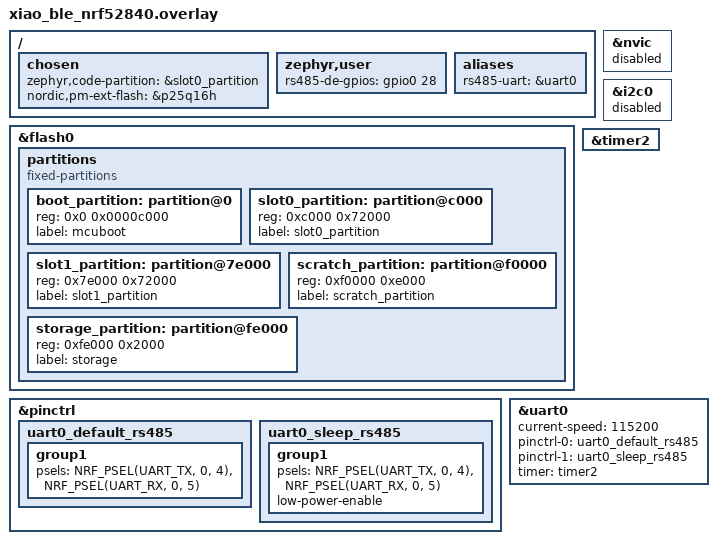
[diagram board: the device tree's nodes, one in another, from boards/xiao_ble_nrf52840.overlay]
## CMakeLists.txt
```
cmake_minimum_required(VERSION 3.20.0)

# BLE pairing passkey is injected at build time from the environment so it is
# never committed to source. The build fails (here, before the rest of the
# configure) if the variable is unset. The value must be a 6-digit number (the
# BLE passkey format; tools/ble-client reads the same variable). It is later
# passed to the app as a string literal and parsed in src/ble_transport.c so a
# value with leading zeros is not read as octal.
if(NOT DEFINED ENV{FLEXIT_CS60_CONTROL_BLE_KEY})
    message(FATAL_ERROR
        "FLEXIT_CS60_CONTROL_BLE_KEY is not set. Export the 6-digit BLE pairing "
        "passkey before building, e.g.\n"
        "    export FLEXIT_CS60_CONTROL_BLE_KEY=444999")
endif()
set(ble_passkey "$ENV{FLEXIT_CS60_CONTROL_BLE_KEY}")
if(NOT ble_passkey MATCHES "^[0-9][0-9][0-9][0-9][0-9][0-9]$")
    message(FATAL_ERROR
        "FLEXIT_CS60_CONTROL_BLE_KEY must be a 6-digit number (got '${ble_passkey}').")
endif()

# Zigbee was removed from the main NCS in v3.0 and now ships as the out-of-tree
# ncs-zigbee add-on. Register it as an extra Zephyr module so the app image can
# pull in the ZBOSS stack. Override on the command line with
# -DZEPHYR_EXTRA_MODULES=<path> if the add-on lives elsewhere.
if(NOT DEFINED ZEPHYR_EXTRA_MODULES)
    set(ZEPHYR_EXTRA_MODULES "$ENV{HOME}/ncs/v3.4.0/ncs-zigbee")
endif()

find_package(Zephyr REQUIRED HINTS $ENV{ZEPHYR_BASE})

project(flexit-cs60-control)

# Bake the validated passkey (checked at the top of this file) into the app as a
# string literal; src/ble_transport.c parses it. zephyr_compile_definitions is
# only available after find_package(Zephyr), hence the split from the check.
zephyr_compile_definitions(FLEXIT_BLE_PASSKEY="${ble_passkey}")

# ZBOSS's built-in "include all ZCL clusters" set (ncs-zigbee zb_vendor.h) omits
# Analog Input, so its server (zcl_analog_input.c) is not compiled and its
# init_server symbol is missing at link. Define the support flag image-wide so
# the cluster source is built and the API header is pulled in. Used by the
# percentage Analog Input endpoints (EP5/EP6) in src/zigbee_ep.c.
zephyr_compile_definitions(ZB_ZCL_SUPPORT_CLUSTER_ANALOG_INPUT)

# Likewise Analog Value (0x000E) is omitted from the built-in set; it backs the
# writable temperature-setpoint endpoint (EP7) in src/zigbee_ep.c.
zephyr_compile_definitions(ZB_ZCL_SUPPORT_CLUSTER_ANALOG_VALUE)

target_sources(app PRIVATE
    src/main.c
    src/ble_transport.c
    src/flexit_bridge.c
    src/flexit_slave.c
    src/panel_mirror.c
    src/rs485_uart.c
    src/zigbee_ep.c
)
```

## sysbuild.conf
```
# Enable MCUboot bootloader compilation via Sysbuild
SB_CONFIG_BOOTLOADER_MCUBOOT=y

# The Zigbee add-on requires Partition Manager (it selects PM_SINGLE_IMAGE and
# addresses the ZBOSS NVRAM via PM_* partitions). Enable it and provide the
# layout in pm_static_xiao_ble_nrf52840.yml. MCUboot defaults to
# swap-using-move, so no scratch partition is needed.
SB_CONFIG_PARTITION_MANAGER=y

# Place the MCUboot secondary (DFU staging) slot in the XIAO BLE's onboard 2 MB
# QSPI flash instead of internal flash. This frees ~half of the 1 MB internal
# flash so the BLE + Zigbee image fits comfortably in a single large primary
# slot. Requires nordic,pm-ext-flash chosen in the app + mcuboot DTS overlays
# and the QSPI NOR driver in both images.
SB_CONFIG_PM_EXTERNAL_FLASH_MCUBOOT_SECONDARY=y
```

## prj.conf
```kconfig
CONFIG_GPIO=y
CONFIG_BOOTLOADER_MCUBOOT=y

# Logging via the existing CDC-ACM console (printk goes here too).
CONFIG_LOG=y

# --- MCUmgr / SMP server over the CDC-ACM UART ---
# The board already chooses zephyr,uart-mcumgr = &board_cdc_acm_uart,
# so the UART transport lands on USB CDC-ACM automatically.
CONFIG_MCUMGR=y
# Since NCS v3.4.0 MCUMGR_TRANSPORT_UART *depends on* UART_MCUMGR (it used to
# select it). Without this line the UART transport is silently dropped and USB
# DFU recovery is lost — keep it.
CONFIG_UART_MCUMGR=y
CONFIG_MCUMGR_TRANSPORT_UART=y

# Command groups exposed over SMP.
# Image upload/list/test/confirm; OS reset is part of the OS group.
CONFIG_MCUMGR_GRP_IMG=y
CONFIG_MCUMGR_GRP_OS=y

# Backing store for image uploads: writes the blob into MCUboot's secondary slot.
CONFIG_IMG_MANAGER=y
CONFIG_STREAM_FLASH=y
CONFIG_FLASH=y
CONFIG_FLASH_MAP=y

# Dependencies pulled in by MCUmgr.
CONFIG_ZCBOR=y
CONFIG_BASE64=y
CONFIG_CRC=y

# A bit more stack/heap for the SMP processing thread and BLE host work.
CONFIG_MAIN_STACK_SIZE=4096
CONFIG_SYSTEM_WORKQUEUE_STACK_SIZE=4096

# RS-485 receive on UART0 (D4=RX, D5=TX, D2=DE/RE) via the
# XIAO-RS485-Expansion-Board. The async UART API drives the UARTE peripheral
# in continuous DMA mode (double-buffered, 256 B per buffer = ~22 ms of
# headroom at 115200 baud) so long bursts can't be lost while BLE host work
# briefly delays the application.
CONFIG_SERIAL=y
CONFIG_UART_ASYNC_API=y
# MCUMGR_TRANSPORT_UART forces UART_INTERRUPT_DRIVEN=y globally for the
# CDC-ACM console, which would also pick uart0 into IRQ mode and lock
# UART_0_ASYNC out. Pin uart0 to async-only here.
CONFIG_UART_0_INTERRUPT_DRIVEN=n
CONFIG_RING_BUFFER=y

# --- Bluetooth Low Energy ---
# Peripheral that exposes:
#   - SMP service (DFU over BLE, gated by passkey-authenticated pairing)
#   - Nordic UART Service (console output mirror)
CONFIG_BT=y
CONFIG_BT_PERIPHERAL=y
CONFIG_BT_DEVICE_NAME="flexit-cs60-control"
CONFIG_BT_MAX_CONN=1
CONFIG_BT_RX_STACK_SIZE=2048

# Security Manager + app-provided passkey (set at build time from
# $FLEXIT_CS60_CONTROL_BLE_KEY, see CMakeLists.txt). Bonding is enabled and persisted in NVS
# (storage_partition in the board overlay) so macOS can reconnect using the
# stored LTK without a fresh passkey prompt. The storage partition lives at
# the end of flash, outside MCUboot's slots/scratch, so the bond survives
# firmware DFU swaps as well.
CONFIG_BT_SMP=y
CONFIG_BT_APP_PASSKEY=y
CONFIG_BT_BONDABLE=y

# LE Secure Connections generates a P-256 key pair via the PSA crypto stack
# (nRF Security). Two resources must be sized for this, or BLE pairing — and
# therefore BLE DFU — fails:
#   1. mbedTLS heap. The Kconfig default (512 B) is far too small:
#      psa_generate_key() fails with PSA_ERROR_INSUFFICIENT_MEMORY (-141), the
#      local public key is never produced, and SC pairing stalls after the
#      peer's public key arrives, timing out after 30 s.
#   2. The BLE "long workqueue" stack. ecc.c runs the (stack-heavy) P-256
#      keygen on bt_long_wq; the 1800 B default overflows mid-keygen once the
#      heap is large enough for the computation to actually run, tripping the
#      MPU stack guard and faulting at boot.
# Sized here for ECC keygen alongside the concurrent Zigbee/ZBOSS crypto. 8192
# was enough on a freshly-booted device but still too tight in the field: it
# shares the heap with active ZBOSS crypto, so once Zigbee has consumed heap a
# *fresh* SC pairing intermittently stalls at -141 (a just-booted device pairs
# fine, and bond reuse needs no keygen, both of which masked it). 16384 gives
# keygen headroom over concurrent ZBOSS.
CONFIG_MBEDTLS_HEAP_SIZE=16384
CONFIG_BT_LONG_WQ_STACK_SIZE=4096

# Always-on device: reboot on a fatal error instead of halting. Also makes an
# unconfirmed DFU test image that faults revert cleanly on the auto-reset
# (MCUboot swaps the previous good image back) rather than wedging the board.
CONFIG_RESET_ON_FATAL_ERROR=y
CONFIG_BT_SETTINGS=y
CONFIG_BT_KEYS_OVERWRITE_OLDEST=y
CONFIG_SETTINGS=y
CONFIG_SETTINGS_NVS=y
CONFIG_NVS=y
CONFIG_FLASH_PAGE_LAYOUT=y

# Larger MTU/ACL buffers for faster DFU throughput.
CONFIG_BT_L2CAP_TX_MTU=498
CONFIG_BT_BUF_ACL_RX_SIZE=502
CONFIG_BT_BUF_ACL_TX_SIZE=502
CONFIG_BT_ATT_PREPARE_COUNT=2

# --- BLE DFU throughput ---
# The big MTU/buffers above are wasted without these. By default the link-layer
# payload (DLE) is capped at 27 B, the connection stays at the central's slow
# default interval, and the radio uses the 1M PHY — so a ~0.5 MB image takes
# ~13 min over BLE. Together these take it to well under a minute:
#   - DLE up to 251 B link-layer payloads (BT_AUTO_DATA_LEN_UPDATE already on).
#   - Auto-switch to the 2M PHY (controller already advertises 2M support).
#   - Let MCUmgr request a fast connection interval while a DFU is in progress.
#   - Advertise SMP buffer params so a client can size its chunks.
#   - Erase the secondary slot progressively instead of all up front.
CONFIG_BT_CTLR_DATA_LENGTH_MAX=251
CONFIG_BT_AUTO_PHY_UPDATE=y
CONFIG_MCUMGR_TRANSPORT_BT_CONN_PARAM_CONTROL=y
CONFIG_MCUMGR_GRP_OS_MCUMGR_PARAMS=y
CONFIG_IMG_ERASE_PROGRESSIVELY=y

# Nordic UART Service (NCS). Gate it to authenticated (passkey-paired)
# connections, same as the SMP transport below. Without this the NUS RX/TX
# characteristics default to plain READ|WRITE permissions, so commands are
# serviced over an unencrypted link before the firmware-initiated security
# upgrade resolves — leaking panel state and accepting mode/setpoint/zbreset
# from unpaired centrals, and making `state` pairing race (unlike `list`,
# whose auth-gated SMP access drives pairing deterministically).
CONFIG_BT_NUS=y
CONFIG_BT_NUS_AUTHEN=y

# SMP/MCUmgr transport over BLE — gated to authenticated (passkey-paired)
# connections only; pair-less centrals get permission errors.
CONFIG_MCUMGR_TRANSPORT_BT=y
CONFIG_MCUMGR_TRANSPORT_BT_REASSEMBLY=y
CONFIG_MCUMGR_TRANSPORT_BT_PERM_RW_AUTHEN=y

# MCUmgr image-upload notification hooks: let the app suspend the Zigbee stack
# while a DFU upload is in flight so the shared 2.4 GHz radio is handed to BLE.
# As a router the 802.15.4 side keeps the radio busy (continuous RX, relaying,
# channel scans), which starves the BLE link and times out a sustained DFU
# upload; zigbee_ep.c hooks DFU_STARTED/STOPPED to suspend/resume ZBOSS. See
# CONFIG_ZIGBEE_DEBUG_FUNCTIONS below.
CONFIG_MCUMGR_MGMT_NOTIFICATION_HOOKS=y
CONFIG_MCUMGR_GRP_IMG_STATUS_HOOKS=y

# Route printk through the log subsystem so the NUS log backend can mirror
# it over BLE. The default UART log backend keeps the USB CDC console alive.
CONFIG_LOG_PRINTK=y
CONFIG_LOG_MODE_DEFERRED=y
CONFIG_LOG_BACKEND_UART=y

# --- Zigbee (802.15.4) router, concurrent with BLE via MPSL ---
# The ncs-zigbee add-on (registered as an extra Zephyr module in CMakeLists)
# provides the ZBOSS stack. This runs a router alongside the BLE peripheral;
# MPSL/the SoftDevice Controller arbitrate the shared radio. Partition layout is
# in pm_static_xiao_ble_nrf52840.yml.
#
# Router (not end device): the XIAO is permanently USB-powered, so there is no
# battery reason to be an end device — and the end-device role caused HA fan/
# setpoint writes to fail. An rx-on-when-idle end device has a single parent and
# relies on it both to deliver downstream frames and to answer route requests on
# its behalf. When the parent ages the child out (or the parent link goes stale)
# the coordinator gets NO_ROUTE / ROUTE_DISCOVERY_UNDERWAY and downstream writes
# die, while the device still blindly pushes reports upstream — so sensors keep
# updating but control silently breaks. A router maintains its own routes (link
# status / route records), is always directly addressable, and is never aged out
# as someone's child, which removes that whole failure class. (Diagnosed from a
# ZHA debug log: cluster 0x0202 FanMode writes to the XIAO returned NO_ROUTE.)
# NOTE: switching role changes the device type in the PAN, so the device must
# leave and re-pair (zbreset + ZHA permit-join) after flashing this build.
CONFIG_ZIGBEE_ADD_ON=y
CONFIG_ZIGBEE_APP_UTILS=y
CONFIG_ZIGBEE_ROLE_ROUTER=y

# Compile in zigbee_debug_suspend/resume_zboss_thread(). zigbee_ep.c calls these
# from the MCUmgr DFU hooks (above) to hand the radio to BLE during a firmware
# upload. The device resets after a successful DFU, so suspending ZBOSS across
# the upload is harmless; an aborted upload resumes it. (The Kconfig help warns
# these can cause instability if misused — here they are only ever used around a
# DFU that ends in a reboot.)
CONFIG_ZIGBEE_DEBUG_FUNCTIONS=y

# Scan all 802.15.4 channels (11-26) to find the Home Assistant coordinator's
# network, rather than the default single-channel (16) mode. Nordic recommends
# CHANNEL_SELECTION_MODE_MULTI when joining a third-party coordinator (ZHA/Z2M),
# since we don't control which channel HA forms its network on.
CONFIG_ZIGBEE_CHANNEL_SELECTION_MODE_MULTI=y

# How long the zigbee is open for pairing after reset/start, when device is not 
# previously paired, or zbreset has been used.
CONFIG_ZIGBEE_DEV_REJOIN_TIMEOUT_MS=60000

# ZBOSS needs a bit more heap than the BLE-only build.
CONFIG_HEAP_MEM_POOL_SIZE=2048

# QSPI NOR driver — the MCUboot DFU secondary slot lives in the XIAO BLE's
# onboard 2 MB QSPI flash (p25q16h), so the app must be able to write the
# uploaded image there via the flash map. This moves the dual-slot pressure off
# the 1 MB internal flash; see smarthouse-integration.md "flash budget".
CONFIG_NORDIC_QSPI_NOR=y
CONFIG_NORDIC_QSPI_NOR_FLASH_LAYOUT_PAGE_SIZE=4096
```

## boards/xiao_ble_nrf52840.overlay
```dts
#include <zephyr/dt-bindings/gpio/gpio.h>

/ {
	chosen {
		zephyr,code-partition = &slot0_partition;
		/* MCUboot DFU secondary slot lives in the onboard 2 MB QSPI flash. */
		nordic,pm-ext-flash = &p25q16h;
	};

	zephyr,user {
		/* XIAO-RS485-Expansion-Board: D2 = SP3485 DE/RE.
		 * HIGH = drive bus (transmit), LOW = high-Z receive.
		 */
		rs485-de-gpios = <&gpio0 28 GPIO_ACTIVE_HIGH>;
	};

	aliases {
		rs485-uart = &uart0;
	};
};

/delete-node/ &code_partition;
/delete-node/ &reserved_partition_0;
/delete-node/ &boot_partition;
/delete-node/ &storage_partition;

&flash0 {
	partitions {
		compatible = "fixed-partitions";
		#address-cells = <1>;
		#size-cells = <1>;

		boot_partition: partition@0 {
			reg = <0x0 0x0000c000>;
			label = "mcuboot";
		};

		slot0_partition: partition@c000 {
			reg = <0xc000 0x72000>;
			label = "slot0_partition";
		};

		slot1_partition: partition@7e000 {
			reg = <0x7e000 0x72000>;
			label = "slot1_partition";
		};

		scratch_partition: partition@f0000 {
			reg = <0xf0000 0xe000>;
			label = "scratch_partition";
		};

		storage_partition: partition@fe000 {
			reg = <0xfe000 0x2000>;
			label = "storage";
		};
	};
};

&nvic {
	status = "disabled";
};

/* The board enables I2C0 on P0.04/P0.05 by default; the RS485 expansion
 * uses those same pins for UART RX/TX, so I2C0 has to release them.
 */
&i2c0 {
	status = "disabled";
};

&pinctrl {
	uart0_default_rs485: uart0_default_rs485 {
		group1 {
			psels = <NRF_PSEL(UART_TX, 0, 4)>,
				<NRF_PSEL(UART_RX, 0, 5)>;
		};
	};

	uart0_sleep_rs485: uart0_sleep_rs485 {
		group1 {
			psels = <NRF_PSEL(UART_TX, 0, 4)>,
				<NRF_PSEL(UART_RX, 0, 5)>;
			low-power-enable;
		};
	};
};

/* TIMER2 is dedicated to UARTE0 as the RX byte counter for the async
 * UART API. Without this, the driver can't reliably count incoming
 * bytes when the bus runs without hardware flow control, and long
 * frames get truncated at buffer-switch boundaries.
 */
&timer2 {
	status = "okay";
};

&uart0 {
	status = "okay";
	current-speed = <115200>;
	pinctrl-0 = <&uart0_default_rs485>;
	pinctrl-1 = <&uart0_sleep_rs485>;
	pinctrl-names = "default", "sleep";
	timer = <&timer2>;
};
```

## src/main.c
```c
#include <zephyr/kernel.h>
#include <zephyr/drivers/gpio.h>
#include <zephyr/drivers/watchdog.h>
#include <zephyr/sys/printk.h>
#include <zephyr/sys/reboot.h>
#include <zephyr/task_wdt/task_wdt.h>

#include "ble_transport.h"
#include "flexit_bridge.h"
#include "flexit_slave.h"
#include "panel_mirror.h"
#include "rs485_uart.h"
#include "zigbee_ep.h"

static const struct gpio_dt_spec red_led =
    GPIO_DT_SPEC_GET(DT_ALIAS(led0), gpios);
static const struct gpio_dt_spec green_led =
    GPIO_DT_SPEC_GET(DT_ALIAS(led1), gpios);
static const struct gpio_dt_spec blue_led =
    GPIO_DT_SPEC_GET(DT_ALIAS(led2), gpios);

/* Status-LED timing. The loop ticks at the fast-blink period; the slower
 * cadences are multiples of it. */
#define LED_TICK_MS          100   /* loop period == fast (joining) blink step */
#define LED_SLOW_BLINK_TICKS 10    /* idle blink: toggle every 1 s            */
#define RED_BLINK_TICKS      5     /* RS485-fault blink: toggle every 500 ms   */
#define ADV_ENSURE_TICKS     10    /* re-check advertising about once a second */

/* The CS60 broadcasts its FC10 status frame continuously (well under a second
 * apart). Treat the RS485 link as down if no valid frame has arrived for this
 * long — generous enough to ride out occasional CRC drops, short enough that a
 * pulled cable or wrong wiring shows on the LED within a few seconds. */
#define RS485_CS60_STALE_MS  5000

/* ---------------------------------------------------------------------------
 * Watchdog
 *
 * The diagnosed field failure is a wedged *system workqueue* (the RS485 drain
 * and Zigbee bridge both run there) while the BLE/SMP threads keep answering —
 * so a watchdog fed only from main() would never fire: main() keeps spinning.
 * We run two task-wdt channels backed by the nRF hardware WDT:
 *   - channel 0 (main): fed every tick from the loop below — catches a hung
 *                       main thread.
 *   - channel 1 (wq):   fed by a heartbeat work item on the system workqueue —
 *                       catches the workqueue wedge, which is the actual fault.
 * task_wdt's expiry runs in the kernel-timer ISR (independent of the
 * workqueue), so a starved channel reboots the SoC even when the workqueue is
 * stuck; MCUboot then re-runs the confirmed image. This automates the manual
 * `ble-client reboot` recovery.
 *
 * Periods are generous: a feed merely has to land within them. The wq heartbeat
 * reschedules far more often than its channel period so ordinary TX stalls in
 * the drain path don't false-trip; only a true wedge (stuck forever inside one
 * work item) lets the channel lapse.
 * ---------------------------------------------------------------------------
 */
#define WDT_MAIN_FEED_PERIOD_MS  5000   /* main loop ticks every LED_TICK_MS */
#define WDT_WQ_HEARTBEAT_MS      1000   /* heartbeat reschedule cadence       */
#define WDT_WQ_FEED_PERIOD_MS    8000   /* workqueue stall tolerated before reset */

static const struct device *const wdt_dev = DEVICE_DT_GET(DT_ALIAS(watchdog0));
static int wdt_main_chan = -1;
static int wdt_wq_chan   = -1;

/* Breadcrumb left for the next boot to report which channel tripped. __noinit
 * RAM survives the cold reset; validated by a magic to ignore power-on garbage. */
static __noinit volatile uint32_t wdt_trip_marker;
#define WDT_TRIP_MAGIC 0x5744u  /* 'WD' */

static const char *wdt_chan_name(uint32_t ch)
{
    switch (ch) {
    case 0:  return "main loop";
    case 1:  return "system-workqueue heartbeat";
    default: return "?";
    }
}

/* Runs in the task_wdt kernel-timer ISR when a channel starves. Deferred
 * logging can't flush here, so leave a RAM breadcrumb, then cold-reset. */
static void wdt_timeout_cb(int channel_id, void *user_data)
{
    ARG_UNUSED(user_data);
    wdt_trip_marker = WDT_TRIP_MAGIC | ((uint32_t)(channel_id & 0xFF) << 16);
    sys_reboot(SYS_REBOOT_COLD);
}

static void wdt_wq_heartbeat_fn(struct k_work *work);
static K_WORK_DELAYABLE_DEFINE(wdt_wq_heartbeat, wdt_wq_heartbeat_fn);

static void wdt_wq_heartbeat_fn(struct k_work *work)
{
    ARG_UNUSED(work);
    if (wdt_wq_chan >= 0) {
        (void)task_wdt_feed(wdt_wq_chan);
    }
    k_work_reschedule(&wdt_wq_heartbeat, K_MSEC(WDT_WQ_HEARTBEAT_MS));
}

/* Report any watchdog reset from the previous boot, then clear the breadcrumb. */
static void watchdog_report_prior_trip(void)
{
    if ((wdt_trip_marker & 0xFFFFu) == WDT_TRIP_MAGIC) {
        uint32_t ch = (wdt_trip_marker >> 16) & 0xFFu;
        printk("WATCHDOG: previous boot was reset by task-wdt channel %u (%s)\n",
               ch, wdt_chan_name(ch));
    }
    wdt_trip_marker = 0;
}

/* Best-effort: install the two channels and start the workqueue heartbeat.
 * A missing/unready WDT is logged but not fatal — the device still runs. */
static void watchdog_init(void)
{
    if (!device_is_ready(wdt_dev)) {
        printk("warning: watchdog device not ready — running without watchdog\n");
        return;
    }

    int err = task_wdt_init(wdt_dev);
    if (err) {
        printk("warning: task_wdt_init failed: %d — running without watchdog\n", err);
        return;
    }

    /* Add order fixes the channel ids the breadcrumb decodes: 0=main, 1=wq. */
    wdt_main_chan = task_wdt_add(WDT_MAIN_FEED_PERIOD_MS, wdt_timeout_cb, NULL);
    wdt_wq_chan   = task_wdt_add(WDT_WQ_FEED_PERIOD_MS, wdt_timeout_cb, NULL);
    if (wdt_main_chan < 0 || wdt_wq_chan < 0) {
        printk("warning: task_wdt_add failed (main=%d wq=%d)\n",
               wdt_main_chan, wdt_wq_chan);
        return;
    }

    k_work_reschedule(&wdt_wq_heartbeat, K_MSEC(WDT_WQ_HEARTBEAT_MS));
    printk("watchdog: task_wdt up (main=%u ms, workqueue=%u ms)\n",
           WDT_MAIN_FEED_PERIOD_MS, WDT_WQ_FEED_PERIOD_MS);
}

int main(void)
{
    printk("flexit-cs60-control starting..\n");

    /* Surface a watchdog reset from the previous boot before anything else, so
     * a field hang leaves a fingerprint in the console/NUS log. */
    watchdog_report_prior_trip();

    gpio_pin_configure_dt(&red_led, GPIO_OUTPUT_INACTIVE);
    gpio_pin_configure_dt(&green_led, GPIO_OUTPUT_INACTIVE);
    gpio_pin_configure_dt(&blue_led, GPIO_OUTPUT_INACTIVE);

    /* Latch any init failure so the red LED can flag it below. Each subsystem
     * still runs best-effort (we don't bail out), so a single failure doesn't
     * take down the others — the LED is the operator's signal that something
     * came up degraded. */
    bool init_failed = false;

    if (rs485_uart_init() < 0) {
        printk("warning: RS485 UART init failed — continuing without RS485 receive\n");
        init_failed = true;
    }

    if (flexit_slave_init() < 0) {
        printk("warning: Flexit Modbus slave init failed\n");
        init_failed = true;
    }

    if (ble_transport_init() < 0) {
        printk("error: BLE transport init failed\n");
        init_failed = true;
    }

    if (zigbee_ep_init() < 0) {
        printk("warning: Zigbee init failed — continuing with BLE only\n");
        init_failed = true;
    }

    if (flexit_bridge_init() < 0) {
        printk("warning: Flexit bridge init failed\n");
        init_failed = true;
    }


    /* Status LEDs:
     *   red (fault):
     *     - solid on if any subsystem init failed
     *     - else blink (500 ms) if the RS485 link to the CS60 is down
     *       (no recent FC10 frame — miswired/unpaired bus or CS60 absent)
     *     - else off
     *   green (Zigbee):
     *     - Zigbee join window open  -> fast blink (toggle every 100 ms)
     *     - Zigbee joined            -> solid on
     *     - otherwise                -> slow blink (toggle every 1 s)
     *   blue (BLE):
     *     - solid on while a central is connected, else off
     */
    /* Start the watchdog only now that subsystem init is done, so the lengthy
     * one-time init (BLE keygen etc.) can't trip a freshly-added channel. */
    watchdog_init();

    for (uint32_t tick = 0;; tick++) {
        if (wdt_main_chan >= 0) {
            (void)task_wdt_feed(wdt_main_chan);
        }

        /* Red: init failure is latched-solid and outranks the link-down blink. */
        if (init_failed) {
            gpio_pin_set_dt(&red_led, 1);
        } else if (!panel_mirror_cs60_link_up(RS485_CS60_STALE_MS)) {
            if (tick % RED_BLINK_TICKS == 0) {
                gpio_pin_toggle_dt(&red_led);
            }
        } else {
            gpio_pin_set_dt(&red_led, 0);
        }

        switch (zigbee_ep_net_state()) {
        case ZIGBEE_NET_JOINING:
            gpio_pin_toggle_dt(&green_led);
            break;
        case ZIGBEE_NET_JOINED:
            gpio_pin_set_dt(&green_led, 1);
            break;
        case ZIGBEE_NET_IDLE:
        default:
            if (tick % LED_SLOW_BLINK_TICKS == 0) {
                gpio_pin_toggle_dt(&green_led);
            }
            break;
        }

        /* Blue LED: solid on while a BLE central is connected, else off. */
        gpio_pin_set_dt(&blue_led, ble_transport_is_connected() ? 1 : 0);

        if (tick % ADV_ENSURE_TICKS == 0) {
            ble_transport_ensure_advertising();
        }

        k_msleep(LED_TICK_MS);
    }

    return 0;
}
```

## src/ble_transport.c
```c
#include "ble_transport.h"
#include "flexit_slave.h"
#include "panel_mirror.h"
#include "zigbee_ep.h"

#include <stdio.h>
#include <stdlib.h>
#include <string.h>
#include <zephyr/kernel.h>
#include <zephyr/sys/atomic.h>
#include <zephyr/sys/printk.h>
#include <zephyr/sys/util.h>

#include <zephyr/bluetooth/bluetooth.h>
#include <zephyr/bluetooth/conn.h>
#include <zephyr/bluetooth/gatt.h>
#include <zephyr/bluetooth/hci.h>
#include <zephyr/bluetooth/uuid.h>

#include <zephyr/settings/settings.h>

#include <bluetooth/services/nus.h>

/*
 * BLE pairing passkey, injected at build time from $FLEXIT_CS60_CONTROL_BLE_KEY
 * via CMake (-DFLEXIT_BLE_PASSKEY="<6 digits>"). It is parsed from a string
 * rather than used as a bare integer so a leading zero is not read as octal.
 * The CMake build fails when the environment variable is unset, so this guard
 * only ever trips on a build that bypasses CMakeLists.txt.
 */
#ifndef FLEXIT_BLE_PASSKEY
#error "FLEXIT_BLE_PASSKEY undefined: set FLEXIT_CS60_CONTROL_BLE_KEY at build time"
#endif

static uint32_t fixed_passkey(void)
{
    return (uint32_t)strtoul(FLEXIT_BLE_PASSKEY, NULL, 10);
}

static struct bt_conn *current_conn;

/* ---------------------------------------------------------------------------
 * RS485 live streaming
 *
 * When active, raw RS485 bytes are forwarded over NUS TX as they arrive
 * from the UART drain timer. The client enables streaming by sending the
 * "stream" command and disables it with "stop". Streaming is also cleared
 * automatically on disconnect.
 * ---------------------------------------------------------------------------
 */
static atomic_t stream_active = ATOMIC_INIT(0);

void ble_transport_forward_rs485(const uint8_t *data, size_t len)
{
    if (!atomic_get(&stream_active) || !current_conn || len == 0) {
        return;
    }

    /* bt_nus_send() requires the payload to fit within ATT_MTU - 3.
     * Query the negotiated MTU; fall back to 20 (BLE default) if not yet
     * exchanged. Remaining bytes are dropped on TX pool exhaustion.
     */
    uint16_t att_mtu   = bt_gatt_get_mtu(current_conn);
    uint16_t chunk_max = (att_mtu > 3u) ? (att_mtu - 3u) : 20u;

    size_t off = 0;
    while (off < len) {
        uint16_t chunk = (uint16_t)MIN(len - off, (size_t)chunk_max);
        if (bt_nus_send(current_conn, data + off, chunk) != 0) {
            break; /* TX pool full or disconnected — drop remainder */
        }
        off += chunk;
    }
}

/* ---------------------------------------------------------------------------
 * Advertising helpers
 * ---------------------------------------------------------------------------
 */
static const struct bt_data ad[] = {
    BT_DATA_BYTES(BT_DATA_FLAGS, (BT_LE_AD_GENERAL | BT_LE_AD_NO_BREDR)),
    BT_DATA(BT_DATA_NAME_COMPLETE, CONFIG_BT_DEVICE_NAME,
            sizeof(CONFIG_BT_DEVICE_NAME) - 1),
};

static const struct bt_data sd[] = {
    BT_DATA_BYTES(BT_DATA_UUID128_ALL, BT_UUID_NUS_VAL),
};

/* Connectable advertising at the GAP "slow" interval (1.0-1.2 s) instead of
 * fast (30-60 ms). The device advertises whenever no central is connected —
 * i.e. nearly all the time — and every advertising event takes the shared
 * 2.4 GHz radio away from the 802.15.4 side via MPSL. At the fast rate that is
 * ~20-30 events/s, which can make the Zigbee router miss incoming frames
 * (coordinator sees MAC_NO_ACK / failed FanMode or setpoint writes). BLE is
 * only used for occasional maintenance, so ~1 s extra discovery latency for
 * ble-client is an acceptable trade.
 */
#define ADV_CONN_SLOW \
    BT_LE_ADV_PARAM(BT_LE_ADV_OPT_CONN, BT_GAP_ADV_SLOW_INT_MIN, \
                    BT_GAP_ADV_SLOW_INT_MAX, NULL)

static void advertising_start(void)
{
    int err = bt_le_adv_start(ADV_CONN_SLOW, ad, ARRAY_SIZE(ad),
                              sd, ARRAY_SIZE(sd));
    if (err == 0) {
        printk("BLE advertising (re)started\n");
    } else if (err != -EALREADY) {
        printk("bt_le_adv_start failed: %d\n", err);
    }
}

void ble_transport_ensure_advertising(void)
{
    if (current_conn == NULL) {
        advertising_start();
    }
}

bool ble_transport_is_connected(void)
{
    return current_conn != NULL;
}

static void adv_restart_work_handler(struct k_work *work)
{
    ARG_UNUSED(work);
    if (current_conn == NULL) {
        advertising_start();
    }
}

static K_WORK_DEFINE(adv_restart_work, adv_restart_work_handler);

/* ---------------------------------------------------------------------------
 * Connection callbacks
 * ---------------------------------------------------------------------------
 */
static void connected(struct bt_conn *conn, uint8_t err)
{
    char addr[BT_ADDR_LE_STR_LEN];
    bt_addr_le_to_str(bt_conn_get_dst(conn), addr, sizeof(addr));

    if (err) {
        printk("BLE connect failed (%s): 0x%02x\n", addr, err);
        return;
    }

    current_conn = bt_conn_ref(conn);
    printk("BLE connected: %s\n", addr);

    int sec = bt_conn_set_security(conn, BT_SECURITY_L3);
    if (sec) {
        printk("bt_conn_set_security failed: %d\n", sec);
        bt_conn_disconnect(conn, BT_HCI_ERR_AUTH_FAIL);
    }
}

static void disconnected(struct bt_conn *conn, uint8_t reason)
{
    char addr[BT_ADDR_LE_STR_LEN];
    bt_addr_le_to_str(bt_conn_get_dst(conn), addr, sizeof(addr));
    printk("BLE disconnected: %s (reason 0x%02x)\n", addr, reason);

    atomic_set(&stream_active, 0);

    if (current_conn == conn) {
        bt_conn_unref(current_conn);
        current_conn = NULL;
    }

    k_work_submit(&adv_restart_work);
}

static void security_changed(struct bt_conn *conn, bt_security_t level,
                             enum bt_security_err err)
{
    char addr[BT_ADDR_LE_STR_LEN];
    bt_addr_le_to_str(bt_conn_get_dst(conn), addr, sizeof(addr));

    /* Reject not just hard failures (err) but also a link that came up below
     * the L3 we requested in connected(). Without the level check, a pairing
     * that downgrades to unauthenticated "Just Works" (level 2) completes with
     * err==0 and is accepted — defeating the passkey, since the passkey is
     * never exchanged in Just Works. Dropping anything < L3 forces a real
     * authenticated (MITM passkey) pairing.
     */
    if (err || level < BT_SECURITY_L3) {
        printk("BLE security insufficient (%s): level %u, err 0x%02x — disconnecting\n",
               addr, level, err);
        bt_conn_disconnect(conn, BT_HCI_ERR_AUTH_FAIL);
        return;
    }

    printk("BLE security raised (%s): level %u (authenticated)\n", addr, level);
}

BT_CONN_CB_DEFINE(conn_callbacks) = {
    .connected        = connected,
    .disconnected     = disconnected,
    .security_changed = security_changed,
};

/* ---------------------------------------------------------------------------
 * Pairing / auth callbacks
 * ---------------------------------------------------------------------------
 */
static uint32_t auth_app_passkey(struct bt_conn *conn)
{
    char addr[BT_ADDR_LE_STR_LEN];
    uint32_t passkey = fixed_passkey();

    bt_addr_le_to_str(bt_conn_get_dst(conn), addr, sizeof(addr));
    printk("BLE passkey for %s: %06u\n", addr, passkey);
    return passkey;
}

static void auth_cancel(struct bt_conn *conn)
{
    char addr[BT_ADDR_LE_STR_LEN];
    bt_addr_le_to_str(bt_conn_get_dst(conn), addr, sizeof(addr));
    printk("BLE pairing cancelled: %s\n", addr);
}

static const struct bt_conn_auth_cb auth_cb = {
    .app_passkey = auth_app_passkey,
    .cancel      = auth_cancel,
};

static void pairing_complete(struct bt_conn *conn, bool bonded)
{
    char addr[BT_ADDR_LE_STR_LEN];
    bt_addr_le_to_str(bt_conn_get_dst(conn), addr, sizeof(addr));
    printk("BLE pairing complete: %s (bonded=%d)\n", addr, bonded);
}

static void pairing_failed(struct bt_conn *conn, enum bt_security_err reason)
{
    char addr[BT_ADDR_LE_STR_LEN];
    bt_addr_le_to_str(bt_conn_get_dst(conn), addr, sizeof(addr));
    printk("BLE pairing failed: %s (reason 0x%02x)\n", addr, reason);
}

static struct bt_conn_auth_info_cb auth_info_cb = {
    .pairing_complete = pairing_complete,
    .pairing_failed   = pairing_failed,
};

/* ---------------------------------------------------------------------------
 * `state` command — render the panel-mirror snapshot
 *
 * Single-line ASCII, key=value pairs separated by spaces, terminated by '\n'.
 * Temperatures are formatted as `N.D` (one decimal, ×10 raw); sensors that
 * are not present surface as "n/a". The line is appended with one
 * `CNT[0xAAAA]=VVVV@Ts` slot per observed FC06 counter. The whole thing
 * fits in one ATT MTU (498-3 = 495 bytes; the line tops out around ~360).
 * ---------------------------------------------------------------------------
 */
static void format_temp_x10(char *out, size_t cap, int16_t x10, bool present)
{
    if (!present) {
        snprintf(out, cap, "n/a");
        return;
    }
    if (x10 < 0) {
        snprintf(out, cap, "-%d.%d", (-x10) / 10, (-x10) % 10);
    } else {
        snprintf(out, cap, "%d.%d", x10 / 10, x10 % 10);
    }
}

static size_t format_state_line(char *buf, size_t cap)
{
    struct panel_mirror_state s;
    panel_mirror_snapshot(&s);

    char t_set[16], t_set2[16], t_sup[16], t_ext[16], t_out[16], t_ret[16];
    format_temp_x10(t_set,  sizeof(t_set),  s.temp_setpoint_x10,     true);
    format_temp_x10(t_set2, sizeof(t_set2), s.temp_setpoint_2_x10,   true);
    format_temp_x10(t_sup,  sizeof(t_sup),  s.temp_supply_air_x10,   true);
    format_temp_x10(t_out,  sizeof(t_out),  s.temp_outdoor_air_x10,  true);
    format_temp_x10(t_ext,  sizeof(t_ext),  s.temp_extract_air_x10,
                    (s.sensors_present & PANEL_MIRROR_SENSOR_EXTRACT_AIR) != 0);
    format_temp_x10(t_ret,  sizeof(t_ret),  s.temp_return_water_x10,
                    (s.sensors_present & PANEL_MIRROR_SENSOR_RETURN_WATER) != 0);

    int w = snprintf(buf, cap,
        "MODE=%u SET=%s SET2=%s "
        "T_SUP=%s T_EXT=%s T_OUT=%s T_RET=%s "
        "PCT_COOL=%u PCT_HX=%u PCT_HEAT=%u PCT_FAN=%u "
        "UNK1=0x%04X UNK2=0x%04X "
        "FC10=%u FC06=%u CRCERR=%u LAST_MS=%llu",
        s.mode, t_set, t_set2,
        t_sup, t_ext, t_out, t_ret,
        s.pct_cooling, s.pct_heat_exchanger, s.pct_heating, s.pct_supply_fan,
        s.unknown_1, s.unknown_2,
        s.fc10_frames, s.fc06_frames, s.crc_failures,
        (unsigned long long)s.last_fc10_uptime_ms);

    if (w < 0) {
        return 0;
    }
    size_t pos = ((size_t)w < cap) ? (size_t)w : cap - 1;

    /* Append slave-side cycle state so the client can watch the mode
     * change progress without a separate command. MODE_QUEUED is what the
     * BLE side asked for; MODE_ACKED reflects the FC65 that closes the
     * cycle. Either may be "none" before the first command of the boot.
     */
    struct flexit_slave_snapshot sl;
    flexit_slave_snapshot(&sl);
    if (pos < cap - 1) {
        if (sl.pending_mode == 0xFFFFu) {
            w = snprintf(buf + pos, cap - pos, " MODE_QUEUED=none");
        } else {
            w = snprintf(buf + pos, cap - pos, " MODE_QUEUED=%u",
                         sl.pending_mode);
        }
        if (w > 0 && (size_t)w < cap - pos) {
            pos += (size_t)w;
        }
    }
    if (pos < cap - 1) {
        if (sl.last_acked_mode == 0xFFFFu) {
            w = snprintf(buf + pos, cap - pos, " MODE_ACKED=none");
        } else {
            w = snprintf(buf + pos, cap - pos,
                         " MODE_ACKED=%u@%llu",
                         sl.last_acked_mode,
                         (unsigned long long)sl.last_ack_uptime_ms);
        }
        if (w > 0 && (size_t)w < cap - pos) {
            pos += (size_t)w;
        }
    }
    if (pos < cap - 1) {
        w = snprintf(buf + pos, cap - pos,
                     " SLV_FC01=%u SLV_FC03=%u SLV_FC04=%u SLV_FC65=%u SLV_COIL0=%u",
                     sl.fc01_serviced, sl.fc03_serviced, sl.fc04_serviced,
                     sl.fc65_acks, sl.coil0_pending ? 1u : 0u);
        if (w > 0 && (size_t)w < cap - pos) {
            pos += (size_t)w;
        }
    }

    /* Setpoint command diagnostics (coil 12 / reg 0x000C). SP_COIL12 should
     * pulse 1 then drop to 0 as the CS60 reads the value; SP_READS counts the
     * FC03 reads served. SET2 (0x00C2) is the committed value to watch.
     */
    if (pos < cap - 1) {
        if (sl.pending_setpoint == 0xFFFFu) {
            w = snprintf(buf + pos, cap - pos,
                         " SP_QUEUED=none SP_COIL12=%u SP_READS=%u",
                         sl.coil_setpoint_pending ? 1u : 0u, sl.setpoint_reads);
        } else {
            w = snprintf(buf + pos, cap - pos,
                         " SP_QUEUED=%u.%u SP_REG=%u SP_COIL12=%u SP_READS=%u",
                         sl.pending_setpoint / 10u, sl.pending_setpoint % 10u,
                         sl.reg_setpoint_value,
                         sl.coil_setpoint_pending ? 1u : 0u, sl.setpoint_reads);
        }
        if (w > 0 && (size_t)w < cap - pos) {
            pos += (size_t)w;
        }
    }

    uint64_t now = (uint64_t)k_uptime_get();
    for (int i = 0; i < PANEL_MIRROR_COUNTER_SLOTS && pos < cap - 1; i++) {
        if (!s.counters[i].used) {
            continue;
        }
        uint64_t age_s = (now - s.counters[i].at_ms) / 1000u;
        w = snprintf(buf + pos, cap - pos,
                     " CNT[0x%04X]=%u@%llus",
                     s.counters[i].addr, s.counters[i].value,
                     (unsigned long long)age_s);
        if (w < 0) {
            break;
        }
        if ((size_t)w >= cap - pos) {
            pos = cap - 1;
            break;
        }
        pos += (size_t)w;
    }

    if (pos < cap - 1) {
        buf[pos++] = '\n';
    }
    buf[pos] = '\0';
    return pos;
}

/* ---------------------------------------------------------------------------
 * NUS receive — command dispatch
 *
 * Commands (sent by ble-client via NUS RX write):
 *   "stream"  — start forwarding RS485 bytes in real time over NUS TX
 *   "stop"    — stop streaming
 *   "state"   — single-line snapshot of the decoded panel mirror
 *   "zbstate" — single-line Zigbee join state (IDLE/JOINING/JOINED) on NUS TX
 *   "mode N"  — queue a CMD_MODE change (N = 0..3) on the Modbus slave;
 *               echoes "mode: queued=N" or "mode: bad arg" on NUS TX
 *   "setpoint C" — queue a setpoint change (C = °C, optional one decimal, e.g.
 *               "setpoint 20.5"); clamped 10.0-30.0 °C. Echoes
 *               "setpoint: queued=C C" or "setpoint: bad arg" on NUS TX
 *   "zbreset" — Zigbee factory reset: leave the network, clear NVRAM and
 *               reboot so the device steers for a new coordinator on next
 *               boot. Echoes an ack on NUS TX, then the BLE link drops as the
 *               device reboots (~1-5 s later).
 *   "clearbond" — remove the stored BLE pairing bond (device side). Echoes an
 *               ack on NUS TX, then disconnects; the next connection must pair
 *               afresh. The host's `ble-client unpair` sends this and then also
 *               clears the host-side bond, in that order (device-then-host is
 *               the only sequence that avoids a one-sided-bond deadlock).
 * ---------------------------------------------------------------------------
 */

/* clearbond is deferred so the NUS ack notification flushes before we wipe the
 * bond and drop the link. bt_unpair(BT_ID_DEFAULT, NULL) removes every stored
 * bond (there is only ever the one central), erasing the keys from NVS since
 * CONFIG_BT_SETTINGS=y; the explicit disconnect forces the central to re-pair
 * on its next connect rather than reusing the now-stale session.
 */
static void clearbond_work_fn(struct k_work *work)
{
    ARG_UNUSED(work);

    int err = bt_unpair(BT_ID_DEFAULT, NULL);
    printk("clearbond: bt_unpair returned %d\n", err);

    if (current_conn) {
        bt_conn_disconnect(current_conn, BT_HCI_ERR_REMOTE_USER_TERM_CONN);
    }
}
static K_WORK_DELAYABLE_DEFINE(clearbond_work, clearbond_work_fn);

static void nus_received(struct bt_conn *conn, const uint8_t *data, uint16_t len)
{
    printk("NUS RX: %.*s\n", len, (const char *)data);

    if (len >= 6 && memcmp(data, "stream", 6) == 0) {
        printk("stream: started\n");
        atomic_set(&stream_active, 1);

    } else if (len >= 5 && memcmp(data, "state", 5) == 0) {
        char   line[512];
        size_t n = format_state_line(line, sizeof(line));
        int    err = bt_nus_send(conn, (const uint8_t *)line, (uint16_t)n);
        if (err) {
            printk("state: bt_nus_send failed: %d\n", err);
        }

    } else if (len >= 7 && memcmp(data, "zbstate", 7) == 0) {
        /* Report the coarse Zigbee network/join state so it can be read over BLE
         * when neither the USB console nor the status LED is visible. */
        const char *s;
        switch (zigbee_ep_net_state()) {
        case ZIGBEE_NET_JOINING: s = "JOINING (pairing window open)"; break;
        case ZIGBEE_NET_JOINED:  s = "JOINED";                        break;
        default:                 s = "IDLE (not joined)";             break;
        }
        char reply[64];
        int  n = snprintf(reply, sizeof(reply), "zbstate: %s\n", s);
        if (n > 0) {
            (void)bt_nus_send(conn, (const uint8_t *)reply, (uint16_t)n);
        }

    } else if (len >= 4 && memcmp(data, "stop", 4) == 0) {
        printk("stream: stopped\n");
        atomic_set(&stream_active, 0);

    } else if (len >= 7 && memcmp(data, "zbreset", 7) == 0) {
        /* Ack before triggering: zigbee_ep_factory_reset() reboots the device
         * shortly after, which tears down this BLE link.
         */
        static const char reply[] =
            "zbreset: leaving Zigbee network, clearing NVRAM, rebooting\n";
        (void)bt_nus_send(conn, (const uint8_t *)reply, sizeof(reply) - 1);
        printk("zbreset: triggering Zigbee factory reset\n");
        zigbee_ep_factory_reset();

    } else if (len >= 9 && memcmp(data, "clearbond", 9) == 0) {
        /* Ack before clearing: clearbond_work_fn() wipes the bond and drops
         * this link, so the notification must flush first.
         */
        static const char reply[] =
            "clearbond: removing bond, disconnecting (re-pair on next connect)\n";
        (void)bt_nus_send(conn, (const uint8_t *)reply, sizeof(reply) - 1);
        printk("clearbond: scheduling bond removal\n");
        k_work_reschedule(&clearbond_work, K_MSEC(300));

    } else if (len >= 4 && memcmp(data, "mode", 4) == 0) {
        /* Parse the rest of the payload as a decimal integer 0..3. */
        char    buf[16];
        char    reply[40];
        size_t  copy = (len < sizeof(buf) - 1) ? len : sizeof(buf) - 1;
        memcpy(buf, data, copy);
        buf[copy] = '\0';

        char *p = buf + 4;
        while (*p == ' ' || *p == '\t') {
            p++;
        }

        int n_reply;
        if (*p < '0' || *p > '9') {
            n_reply = snprintf(reply, sizeof(reply),
                               "mode: bad arg\n");
        } else {
            int mode = atoi(p);
            int err  = flexit_slave_queue_mode((uint16_t)mode);
            if (err == 0) {
                n_reply = snprintf(reply, sizeof(reply),
                                   "mode: queued=%d\n", mode);
            } else {
                n_reply = snprintf(reply, sizeof(reply),
                                   "mode: bad arg\n");
            }
        }
        if (n_reply > 0) {
            (void)bt_nus_send(conn, (const uint8_t *)reply,
                              (uint16_t)n_reply);
        }

    } else if (len >= 8 && memcmp(data, "setpoint", 8) == 0) {
        /* Parse "setpoint <C>" where C is °C with an optional single decimal
         * (e.g. "20" or "20.5"); convert to °C ×10 and clamp to 10.0-30.0 C.
         * Direct test path for flexit_slave_queue_setpoint() (the same sink the
         * Zigbee Analog Value setpoint write drives).
         */
        char    buf[16];
        char    reply[48];
        size_t  copy = (len < sizeof(buf) - 1) ? len : sizeof(buf) - 1;
        memcpy(buf, data, copy);
        buf[copy] = '\0';

        char *p = buf + 8;
        while (*p == ' ' || *p == '\t') {
            p++;
        }

        int n_reply;
        if (*p < '0' || *p > '9') {
            n_reply = snprintf(reply, sizeof(reply), "setpoint: bad arg\n");
        } else {
            int whole = 0;
            while (*p >= '0' && *p <= '9') {
                whole = whole * 10 + (*p - '0');
                p++;
            }
            int tenths = 0;
            if (*p == '.' && p[1] >= '0' && p[1] <= '9') {
                tenths = p[1] - '0';
            }
            int dc = whole * 10 + tenths;
            if (dc < 100) {
                dc = 100;
            } else if (dc > 300) {
                dc = 300;
            }
            (void)flexit_slave_queue_setpoint((uint16_t)dc);
            n_reply = snprintf(reply, sizeof(reply),
                               "setpoint: queued=%d.%d C\n", dc / 10, dc % 10);
        }
        if (n_reply > 0) {
            (void)bt_nus_send(conn, (const uint8_t *)reply,
                              (uint16_t)n_reply);
        }
    }
}

static struct bt_nus_cb nus_callbacks = {
    .received = nus_received,
};

/* ---------------------------------------------------------------------------
 * Public init
 * ---------------------------------------------------------------------------
 */
int ble_transport_init(void)
{
    int err;

    err = bt_conn_auth_cb_register(&auth_cb);
    if (err) {
        printk("bt_conn_auth_cb_register failed: %d\n", err);
        return err;
    }

    err = bt_conn_auth_info_cb_register(&auth_info_cb);
    if (err) {
        printk("bt_conn_auth_info_cb_register failed: %d\n", err);
        return err;
    }

    err = bt_enable(NULL);
    if (err) {
        printk("bt_enable failed: %d\n", err);
        return err;
    }

    err = settings_load();
    if (err) {
        printk("settings_load failed: %d (continuing without persisted bonds)\n",
               err);
    }

    err = bt_nus_init(&nus_callbacks);
    if (err) {
        printk("bt_nus_init failed: %d\n", err);
        return err;
    }

    advertising_start();

    printk("BLE up: name='%s', passkey=%06u, security required=L3\n",
           CONFIG_BT_DEVICE_NAME, fixed_passkey());
    return 0;
}
```

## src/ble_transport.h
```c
#ifndef FLEXITMC_BLE_TRANSPORT_H_
#define FLEXITMC_BLE_TRANSPORT_H_

#include <stdbool.h>
#include <stddef.h>
#include <stdint.h>

/* Bring up BLE peripheral with:
 *   - SMP-over-BT service for DFU (authenticated/paired access only).
 *   - Nordic UART Service for commands and RS485 data streaming.
 *   - Build-time passkey for pairing; security level L3 forced on connect.
 * Returns 0 on success, negative errno on failure.
 */
int ble_transport_init(void);

/* Idempotent: starts advertising if no BLE connection is currently up. */
void ble_transport_ensure_advertising(void);

/* True while a central is connected. Intended for a status LED; the read is a
 * lock-free snapshot of the connection pointer, so it may momentarily lag a
 * connect/disconnect that is in flight. */
bool ble_transport_is_connected(void);

/* Forward raw RS485 bytes over NUS TX if a client has requested streaming
 * (sent the "stream" command). Called from the rs485_uart drain work handler
 * on the system workqueue. Bytes are dropped silently if the BLE TX pool is
 * exhausted.
 */
void ble_transport_forward_rs485(const uint8_t *data, size_t len);

#endif /* FLEXITMC_BLE_TRANSPORT_H_ */
```

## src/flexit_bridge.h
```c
#ifndef FLEXITMC_FLEXIT_BRIDGE_H_
#define FLEXITMC_FLEXIT_BRIDGE_H_

/* Glue between the RS485 panel mirror and the Zigbee data model.
 *
 * Feeds the zigbee_ep setters with real CS60 data:
 *   - periodically snapshots panel_mirror and pushes supply/outdoor
 *     temperatures and the current mode into the zigbee_ep setters;
 *   - registers the FanMode-write handler so a Zigbee client writing FanMode
 *     injects a real CMD_MODE via flexit_slave_queue_mode().
 *
 * Keeps zigbee_ep.c protocol-agnostic: it only knows its public setter API,
 * while this module owns the RS485-side wiring.
 */

/* Register the FanMode-write handler and start the periodic poll worker. Call
 * once at boot, after zigbee_ep_init(). Returns 0 on success.
 */
int flexit_bridge_init(void);

#endif /* FLEXITMC_FLEXIT_BRIDGE_H_ */
```

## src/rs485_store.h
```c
#ifndef FLEXITMC3_RS485_STORE_H_
#define FLEXITMC3_RS485_STORE_H_

#include <stddef.h>
#include <stdint.h>

/* Capacity of the in-RAM RS485 ring buffer (raw bytes, no framing overhead). */
#define RS485_STORE_SIZE 2048

/* Append raw bytes to the ring. When full, the oldest bytes are silently
 * overwritten. Inputs larger than RS485_STORE_SIZE are clipped to keep only
 * the most-recent RS485_STORE_SIZE bytes. Thread-safe.
 */
void rs485_store_append(const uint8_t *data, size_t len);

/* Copy the current ring contents (oldest byte first) into `out`, up to
 * `max_out` bytes. Returns the number of bytes copied. Thread-safe.
 */
size_t rs485_store_snapshot(uint8_t *out, size_t max_out);

#endif /* FLEXITMC3_RS485_STORE_H_ */
```
